# STM32U335 register map
File version: 1.0
CPU: CM33 r0p1, little endian, MPU, FPU, 4 interrupt priority bits
Registers are 32-bit, read-write, reset 0x0 unless marked. A register's access mark holds for its fields unless they carry their own. Offsets are from the block's base; [hi:lo] are bit positions; {n}, {i} and the like mark numbered series; <NAME> marks a mode.

## FLASH — FLASH register block
Base 0x40022000
Same registers: FLASH_S 0x50022000
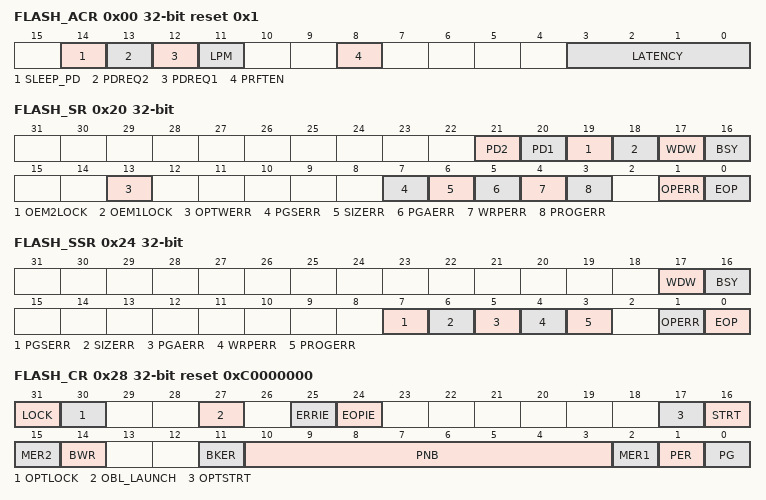
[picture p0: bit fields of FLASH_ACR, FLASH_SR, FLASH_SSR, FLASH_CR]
0x00 FLASH_ACR reset 0x1 — This register is nonsecure. It can be read and written by both secure and nonsecure access. This register can be protected against unprivileged access when PRIV = 1 in FLASH_PRIVCFGR register.
  [14] SLEEP_PD — Flash memory power-down mode during Sleep mode This bit determines whether the flash memory is in power-down mode or Idle mode when the device is in Sleep mode. The flash must not be put in power-down while a program or an erase operation is ongoing.
    0=Flash in Idle mode during Sleep mode; 1=Flash in power-down mode during Sleep mode
  [13] PDREQ2 — Bank 2 power-down mode request This bit is write-protected with FLASH_PDKEY2R. This bit requests bank 2 to enter power-down mode. When bank 2 enters power-down mode, this bit is cleared by hardware and FLASH_PDKEY2R is locked.
    0=No request for bank 2 to enter power-down mode; 1=Bank 2 requested to enter power-down mode
  [12] PDREQ1 — Bank 1 power-down mode request This bit is write-protected with FLASH_PDKEY1R. This bit requests bank 1 to enter power-down mode. When bank 1 enters power-down mode, this bit is cleared by hardware and FLASH_PDKEY1R is locked.
    0=No request for bank 1 to enter power-down mode; 1=Bank 1 requested to enter power-down mode
  [11] LPM — Low-power read mode This bit puts the flash memory in low-power read mode.
    0=FLASH not in low-power read mode; 1=FLASH in low-power read mode
  [8] PRFTEN — Prefetch enable This bit enables the prefetch buffer in the embedded flash memory.
    0=Prefetch disabled; 1=Prefetch enabled
  [3:0] LATENCY — Latency This bit field represents the ratio between the HCLK (AHB clock) period and the flash memory access time. ...
    0=0 wait state; 1=1 wait state; 2=2 wait states; 15=15 wait states
0x08 FLASH_KEYR wo — This register is nonsecure. It can be read and written by both secure and nonsecure access. This register can be protected against unprivileged access when PRIV =1 in FLASH_PRIVCFGR register.
  [31:0] KEY — Flash memory nonsecure key The following values must be written consecutively to unlock the FLASH_CR register, allowing flash memory nonsecure programming/erasing operations: KEY1: 0x4567 0123 KEY2: 0xCDEF 89AB
0x0C FLASH_SKEYR wo — This register is secure. It can be read and written only by secure access. A nonsecure read/write access is RAZ/WI. This register can be protected against unprivileged access when SPRIV = 1 in FLASH_PRIVCFGR register.
  [31:0] KEY — Flash memory secure key The following values must be written consecutively to unlock the FLASH_SCR register, allowing flash memory secure programming/erasing operations: KEY1: 0x4567 0123 KEY2: 0xCDEF 89AB
0x10 FLASH_OPTKEYR wo — This register is nonsecure. It can be read and written by both secure and nonsecure access. This register can be protected against unprivileged access when PRIV = 1 in FLASH_PRIVCFGR register.
  [31:0] KEY — Option-byte key The following values must be written consecutively to unlock the FLASH_OPTR register allowing option-byte programming/erasing operations: KEY1: 0x0819 2A3B KEY2: 0x4C5D 6E7F
0x18 FLASH_PDKEY1R wo — This register is nonsecure. It can be read and written by both secure and nonsecure access. This register can be protected against unprivileged access when PRIV = 1 in FLASH_PRIVCFGR register.
  [31:0] KEY1 — Bank 1 power-down key The following values must be written consecutively to unlock PDREQ1 bit in FLASH_ACR: KEY1_1: 0x0415 2637 KEY1_2: 0xFAFB FCFD
0x1C FLASH_PDKEY2R wo — This register is nonsecure. It can be read and written by both secure and nonsecure access. This register can be protected against unprivileged access when PRIV = 1 in FLASH_PRIVCFGR register.
  [31:0] KEY2 — Bank 2 power-down key The following values must be written consecutively to unlock PDREQ2 bit in FLASH_ACR: KEY2_1: 0x4051 6273 KEY2_2: 0xAFBF CFDF
0x20 FLASH_SR (reset mask 0xFFF0FFFF) — This register is nonsecure. It can be read and written by both secure and nonsecure access. This register can be protected against unprivileged access when PRIV = 1 in FLASH_PRIVCFGR register.
  [21] PD2 ro — Bank 2 in power-down mode This bit indicates that the flash memory bank 2 is in power-down state. It is reset when bank 2 is in normal mode or being awaken.
  [20] PD1 ro — Bank 1 in power-down mode This bit indicates that the flash memory bank 1 is in power-down state. It is reset when bank 1 is in normal mode or being awaken.
  [19] OEM2LOCK ro — OEM2 lock This bit indicates that the OEM2 RDP key read during the OBL is not virgin. When set, the OEM2 RDP lock mechanism is active.
  [18] OEM1LOCK ro — OEM1 lock This bit indicates that the OEM1 RDP key read during the OBL is not virgin. When set, the OEM1 RDP lock mechanism is active.
  [17] WDW ro — Nonsecure wait data to write This bit indicates that the flash memory write buffer has been written by a secure or nonsecure operation. It is set when the first data is stored in the buffer, and cleared when the write is performed in the flash memory.
  [16] BSY ro — Nonsecure busy This bit indicates that a flash memory secure or nonsecure operation is in progress. It is set at the beginning of a flash operation, and reset when the operation finishes or when an error occurs.
  [13] OPTWERR — Option write error This bit is set by hardware when the options bytes are written with an invalid configuration. It is cleared by writing 1. Refer to Section 7.3.8: Flash memory errors flags for full conditions of error flag setting.
  [7] PGSERR — Nonsecure programming sequence error This bit is set by hardware when programming sequence is not correct. It is cleared by writing 1. Refer to Section 7.3.8: Flash memory errors flags for full conditions of error flag setting.
  [6] SIZERR — Nonsecure size error This bit is set by hardware when the size of the access is a byte or half-word during a nonsecure program sequence. Only double-word programming is allowed by means of successive word accesses. This bit is cleared by writing 1.
  [5] PGAERR — Nonsecure programming alignment error This bit is set by hardware when the first word to be programmed is not aligned with a double-word address, or the second does not belong to the same double-word address. This bit is cleared by writing 1.
  [4] WRPERR — Nonsecure write protection error This bit is set by hardware when a nonsecure address to be erased/programmed belongs to a write-protected part (by WRP, HDP, or RDP level 1) of the flash memory. This bit is cleared by writing 1. Refer to Section 7.3.8: Flash memory errors flags for full conditions of error flag setting.
  [3] PROGERR — Nonsecure programming error This bit is set by hardware when a nonsecure double-word address to be programmed contains a value different from all 1 before programming, except if the data to write is all 0. This bit is cleared by writing 1.
  [1] OPERR — Nonsecure operation error This bit is set by hardware when a flash memory nonsecure operation (program/erase) completes unsuccessfully. This bit is set only if nonsecure error interrupts are enabled (ERRIE = 1 in FLASH_CR). This bit is cleared by writing 1.
  [0] EOP — Nonsecure end of operation This bit is set by hardware when one or more flash memory nonsecure operation (program/erase) has been completed successfully. This bit is set only if the nonsecure end of operation interrupts are enabled (EOPIE = 1 in FLASH_CR). This bit is cleared by writing 1.
0x24 FLASH_SSR — This register is secure. It can be read and written only by secure access. A nonsecure read/write access is RAZ/WI. This register can be protected against unprivileged access when SPRIV = 1 in FLASH_PRIVCFGR register.
  [17] WDW ro — Secure wait data to write This bit indicates that the flash memory write buffer has been written by a secure or nonsecure operation. It is set when the first data is stored in the buffer, and cleared when the write is performed in the flash memory.
  [16] BSY ro — Secure busy This bit indicates that a flash memory secure or nonsecure operation is in progress. This is set on the beginning of a flash operation, and reset when the operation finishes or when an error occurs.
  [7] PGSERR — Secure programming sequence error This bit is set by hardware when programming sequence is not correct. It is cleared by writing 1. Refer to Section 7.3.8: Flash memory errors flags for full conditions of error flag setting.
  [6] SIZERR — Secure size error This bit is set by hardware when the size of the access is a byte or half-word during a secure program sequence. Only double-word programming is allowed by means of successive word accesses.This bit is cleared by writing 1.
  [5] PGAERR — Secure programming alignment error This bit is set by hardware when the first word to be programmed is not aligned with a double-word address, or the second word does not belong to the same double-word address.This bit is cleared by writing 1.
  [4] WRPERR — Secure write protection error This bit is set by hardware when a secure address to be erased/programmed belongs to a write-protected part (by WRP, HDP, or RDP level 1) of the flash memory.This bit is cleared by writing 1. Refer to Section 7.3.8: Flash memory errors flags for full conditions of error flag setting.
  [3] PROGERR — Secure programming error This bit is set by hardware when a secure double-word address to be programmed contains a value different from all 1 before programming, except if the data to write is all 0. This bit is cleared by writing 1.
  [1] OPERR — Secure operation error This bit is set by hardware when a flash memory secure operation (program/erase) completes unsuccessfully. This bit is set only if secure error interrupts are enabled (ERRIE = 1 in FLASH_SCR). This bit is cleared by writing 1.
  [0] EOP — Secure end of operation This bit is set by hardware when one or more flash memory secure operation (program/erase) has been completed successfully. This bit is set only if the secure end of operation interrupts are enabled (EOPIE = 1 in FLASH_SCR). This bit is cleared by writing 1.
0x28 FLASH_CR reset 0xC0000000 — This register can only be written when the BSY or OBL_LAUNCH are reset. Otherwise, the write access is stalled until the BSY bits are reset. This register is nonsecure. It can be read and written by both secure and nonsecure access. This register can be protected against unprivileged access when PRIV = 1 in FLASH_PRIVCFGR register.
  [31] LOCK — Nonsecure lock This bit is set only. When set, the FLASH_CR register is locked. It is cleared by hardware after detecting the unlock sequence in FLASH_KEYR register. In case of an unsuccessful unlock operation, this bit remains set until the next system reset.
  [30] OPTLOCK — Option lock This bit is set only. When set, all bits concerning user options in FLASH_CR register are locked. This bit is cleared by hardware after detecting the unlock sequence. The LOCK bit in FLASH_CR must be cleared before doing the unlock sequence for OPTLOCK bit. In case of an unsuccessful unlock operation, this bit remains set until the next reset.
  [27] OBL_LAUNCH — Option-byte loading forced When set to 1, this bit forces the option-byte reloading. This bit is cleared only when the option-byte loading is complete. It cannot be written if OPTLOCK is set.
    0=Option-byte loading complete; 1=Option-byte loading requested
  [25] ERRIE — Nonsecure error interrupt enable This bit enables the interrupt generation when the OPERR bit in FLASH_SR is set to 1.
    0=Nonsecure OPERR error interrupt disabled; 1=Nonsecure OPERR error interrupt enabled
  [24] EOPIE — Nonsecure end of operation interrupt enable This bit enables the interrupt generation when the EOP bit in FLASH_SR is set to 1.
    0=Nonsecure EOP Interrupt disabled; 1=Nonsecure EOP Interrupt enabled
  [17] OPTSTRT — Option modification start This bit triggers an option operation when set. It can not be written if OPTLOCK bit is set. This bit is set only by software, and is cleared when the BSY bit is cleared in FLASH_SR.
  [16] STRT — Nonsecure start This bit triggers a nonsecure erase operation when set. If MER1, MER2, and PER bits are reset, and the STRT bit is set (this configuration is forbidden), the PGSERR bit in FLASH_SR is set . This bit is set only by software and is cleared when the BSY bit is cleared in FLASH_SR.
  [15] MER2 — Nonsecure bank 2 mass erase This bit triggers the bank 2 nonsecure mass erase (all bank 2 user pages) when set.
  [14] BWR — Nonsecure burst write programming mode When set, this bit selects the burst write programming mode.
  [11] BKER — Nonsecure bank selection for page erase
    0=Bank 1 selected for nonsecure page erase; 1=Bank 2 selected for nonsecure page erase
  [10:3] PNB — Nonsecure page number selection These bits select the page to erase. ... PNB[7] is reserved for STM32U375/385
    0=page 0; 1=page 1; 255=page 255
  [2] MER1 — Nonsecure bank 1 mass erase This bit triggers the bank 1 nonsecure mass erase (all bank 1 user pages) when set.
  [1] PER — Nonsecure page erase
    0=Nonsecure page erase disabled; 1=Nonsecure page erase enabled
  [0] PG — Nonsecure programming
    0=Nonsecure FLASH programming disabled; 1=Nonsecure FLASH programming enabled
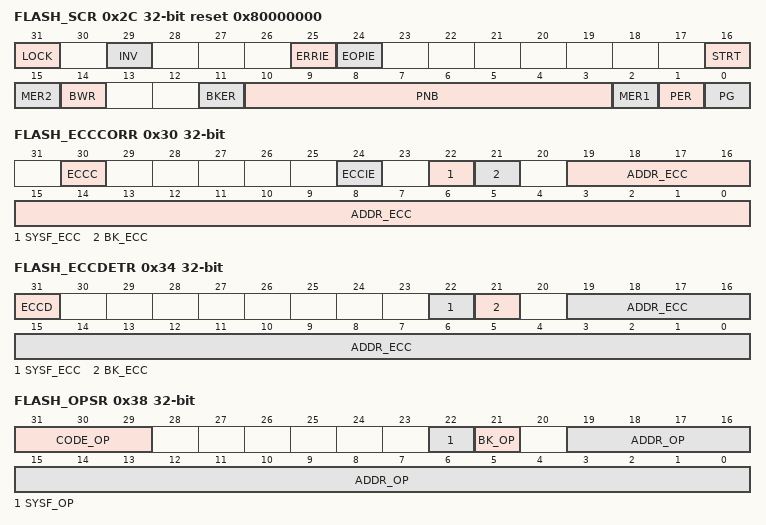
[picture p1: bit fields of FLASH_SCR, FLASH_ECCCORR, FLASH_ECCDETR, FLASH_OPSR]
0x2C FLASH_SCR reset 0x80000000 — This register can only be written when the BSY or OBL_LAUNCH are reset. Otherwise, the write access stalls until the BSY bits are reset. This register is secure. It can be read and written only by secure access. A nonsecure read/write access is RAZ/WI. This register can be protected against unprivileged access when SPRIV = 1 in FLASH_PRIVCFGR register.
  [31] LOCK — Secure lock This bit is set only. When set, the FLASH_SCR register is locked. This bit is cleared by hardware after detecting the unlock sequence in FLASH_SKEYR register. In case of an unsuccessful unlock operation, this bit remains set until the next system reset.
  [29] INV — Flash memory security state invert This bit inverts the flash memory security state.
  [25] ERRIE — Secure error interrupt enable This bit enables the interrupt generation when the OPERR bit in FLASH_SSR is set to 1.
    0=Secure OPERR error interrupt disabled; 1=Secure OPERR error interrupt enabled
  [24] EOPIE — Secure end of operation interrupt enable This bit enables the interrupt generation when the EOP bit in FLASH_SSR is set to 1.
    0=Secure EOP Interrupt disabled; 1=Secure EOP Interrupt enabled
  [16] STRT — Secure start This bit triggers a secure erase operation when set. If MER1, MER2, and PER bits are reset, and the STRT bit is set, the PGSERR in FLASH_SSR is set (this condition is forbidden). This bit is set only by software and is cleared when the BSY bit is cleared in FLASH_SSR.
  [15] MER2 — Secure bank 2 mass erase This bit triggers the bank 2 secure mass erase (all bank 2 user pages) when set.
  [14] BWR — Secure burst write programming mode When set, this bit selects the burst write programming mode.
  [11] BKER — Secure bank selection for page erase
    0=Bank 1 selected for secure page erase; 1=Bank 2 selected for secure page erase
  [10:3] PNB — Secure page number selection These bits select the page to erase: ... Note: PNB[7] is reserved for STM32U375/385
    0=page 0; 1=page 1
  [2] MER1 — Secure bank 1 mass erase This bit triggers the bank 1 secure mass erase (all bank 1 user pages) when set.
  [1] PER — Secure page erase
    0=Secure page erase disabled; 1=Secure page erase enabled
  [0] PG — Secure programming
    0=Secure FLASH programming disabled; 1=Secure FLASH programming enabled
0x30 FLASH_ECCCORR — This register is nonsecure. It can be read and written by both secure and nonsecure access. This register can be protected against unprivileged access when PRIV = 1 in FLASH_PRIVCFGR register.
  [30] ECCC — ECC correction This bit is set by hardware when one ECC error has been detected and corrected (only if ECCC was previously cleared). An interrupt is generated if ECCIE is set. This bit is cleared by writing 1.
  [24] ECCIE — ECC correction interrupt enable This bit enables the interrupt generation when the ECCC bit in FLASH_ECCR is set.
    0=ECCC interrupt disabled; 1=ECCC interrupt enabled
  [22] SYSF_ECC ro — System flash memory ECC fail This bit indicates that the ECC error correction or double ECC error detection is located in the system flash memory.
  [21] BK_ECC ro — ECC fail bank This bit indicates which bank is concerned by the ECC error correction.
    0=Bank 1; 1=Bank 2
  [19:0] ADDR_ECC ro — ECC fail address This bit field indicates which address is concerned by the ECC error correction. The address is given by bank from address 0x0 0000. Note: ADDR_ECC[19] is reserved for STM32U375/385.
0x34 FLASH_ECCDETR — This register is nonsecure. It can be read and written by both secure and nonsecure access. This register can be protected against unprivileged access when PRIV = 1 in FLASH_PRIVCFGR register.
  [31] ECCD — ECC detection This bit is set by hardware when two ECC errors have been detected (only if ECCD was previously cleared). When this bit is set, a NMI is generated. This bit is cleared by writing 1.
  [22] SYSF_ECC ro — System flash memory ECC fail This bit indicates that the double ECC error detection is located in the system flash memory.
  [21] BK_ECC ro — ECC fail bank This bit indicates which bank is concerned by the double ECC error detection.
    0=Bank 1; 1=Bank 2
  [19:0] ADDR_ECC ro — ECC fail address This bit field indicates which address is concerned by the double ECC error detection. The address is given by bank from address 0x0 0000. Note: ADDR_ECC[19] is reserved for STM32U375/385.
0x38 FLASH_OPSR ro (reset mask 0xF000000) — System reset value: 0xX0XX XXXX Power-on reset value: 0xX0XX XXXX This register is nonsecure. It can be read and written by both secure and nonsecure access. This register can be protected against unprivileged access when PRIV = 1 in FLASH_PRIVCFGR register.
  [31:29] CODE_OP — Flash memory operation code This bit field indicates which flash memory operation has been interrupted by a system reset:
    0=No flash operation interrupted by previous reset; 1=Single write operation interrupted; 2=Burst write operation interrupted; 3=Page erase operation interrupted; 4=Bank erase operation interrupted; 5=Mass erase operation interrupted; 6=Option change operation interrupted
  [22] SYSF_OP — Operation in system flash memory interrupted This bit indicates that the reset occurred during an operation in the system flash memory.
  [21] BK_OP — Interrupted operation bank This bit indicates which flash memory bank was accessed when reset occurred
    0=Bank 1; 1=Bank 2
  [19:0] ADDR_OP — Interrupted operation address This bit field indicates which address in the flash memory was accessed when reset occurred. The address is given by bank from address 0x0 0000. Note: ADDR_OP[19] is reserved for STM32U375/385.
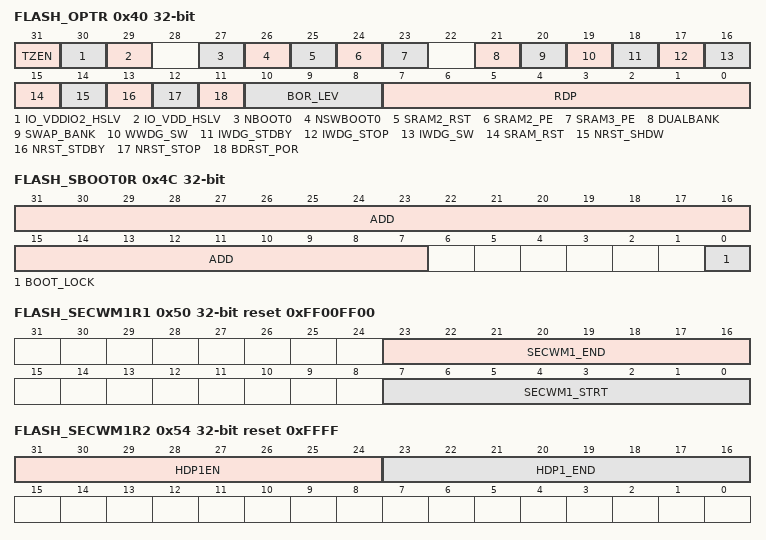
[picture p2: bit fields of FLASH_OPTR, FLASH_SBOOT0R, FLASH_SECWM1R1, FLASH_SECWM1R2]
0x40 FLASH_OPTR reset not defined — This register is nonsecure. It can be read and written by both secure and nonsecure access. This register can be protected against unprivileged access when PRIV = 1 in FLASH_PRIVCFGR register. ST production value: 0x1FEF F0AA (register bits 0 to 31 are loaded with values from the flash memory at OBL)
  [31] TZEN — Global TrustZone security enable
    0=Global TrustZone security disabled; 1=Global TrustZone security enabled
  [30] IO_VDDIO2_HSLV — High-speed I/O at low V<sub>DDIO2</sub> voltage configuration bit This bit can be set only with V<sub>DDIO2</sub> below 2.5 V.
    0=High-speed I/O at low V<sub>DDIO2 </sub>voltage feature disabled (V<sub>DDIO2</sub> can exceed 2.5 V); 1=High-speed I/O at low V<sub>DDIO2 </sub>voltage feature enabled (V<sub>DDIO2</sub> remains below 2.5 V)
  [29] IO_VDD_HSLV — High-speed I/O at low V<sub>DD </sub>voltage configuration bit This bit can be set only with V<sub>DD</sub> below 2.5V
    0=High-speed I/O at low V<sub>DD </sub>voltage feature disabled (V<sub>DD</sub> can exceed 2.5 V); 1=High-speed I/O at low V<sub>DD </sub>voltage feature enabled (V<sub>DD</sub> remains below 2.5 V)
  [27] NBOOT0 — NBOOT0 option bit
    0=NBOOT0 = 0; 1=NBOOT0 = 1
  [26] NSWBOOT0 — Software BOOT0
    0=BOOT0 taken from the option bit NBOOT0; 1=BOOT0 taken from PH3/BOOT0 pin
  [25] SRAM2_RST — SRAM2 erase when system reset
    0=SRAM2 erased when a system reset occurs; 1=SRAM2 not erased when a system reset occurs
  [24] SRAM2_PE — SRAM2 parity check enable
    0=SRAM2 parity check enabled; 1=SRAM2 parity check disabled
  [23] SRAM3_PE — SRAM3 parity check enable
    0=SRAM3 parity check enabled; 1=SRAM3 parity check disabled
  [21] DUALBANK — Dual-bank on 512-Kbyte flash memory devices
    0=Single-bank FLASH with contiguous address in bank 1; 1=Dual-bank FLASH with contiguous addresses
  [20] SWAP_BANK — Swap banks
    0=Bank 1 and bank 2 addresses not swapped; 1=Bank 1 and bank 2 addresses swapped
  [19] WWDG_SW — Window watchdog selection
    0=Hardware WWDG selected; 1=Software WWDG selected
  [18] IWDG_STDBY — Independent watchdog counter freeze in Standby mode
    0=IWDG counter frozen in Standby mode; 1=IWDG counter running in Standby mode
  [17] IWDG_STOP — Independent watchdog counter freeze in Stop mode
    0=IWDG counter frozen in Stop mode; 1=IIWDG counter running in Stop mode
  [16] IWDG_SW — Independent watchdog selection
    0=Hardware IWDG selected; 1=Software IWDG selected
  [15] SRAM_RST — All SRAMs (except SRAM2 and SRAM4) erase upon system reset Note: SRAM4 is not available in STM32U375/385.
    0=All SRAMs (except SRAM2 and SRAM4) erased when a system reset occurs; 1=All SRAMs (except SRAM2 and SRAM4) not erased when a system reset occurs
  [14] NRST_SHDW — Reset generation in Shutdown mode
    0=Reset generated when entering the Shutdown mode; 1=No reset generated when entering the Shutdown mode
  [13] NRST_STDBY — Reset generation in Standby mode
    0=Reset generated when entering the Standby mode; 1=No reset generate when entering the Standby mode
  [12] NRST_STOP — Reset generation in Stop mode
    0=Reset generated when entering the Stop mode; 1=No reset generated when entering the Stop mode
  [11] BDRST_POR — Backup domain reset with power-on reset
    0=The backup domain is not reset after a V<sub>DD</sub> domain brownout reset (BOR). This configuration must be used when V<sub>BAT</sub> supply source is different from V<sub>DD</sub>.; 1=The backup domain is reset after a V<sub>DD</sub> domain brownout reset (BOR). This configuration must be used when the V<sub>BAT</sub> and V<sub>DD</sub> are connected together. It is forbidden when V<sub>BAT</sub> supply source is different from V<sub>DD</sub>.
  [10:8] BOR_LEV — BOR reset level This bit field contains the V<sub>DD</sub> supply level threshold that activates/releases the reset.
    0=BOR level 0 (reset level threshold around 1.7 V); 1=BOR level 1 (reset level threshold around 2.0 V); 2=BOR level 2 (reset level threshold around 2.2 V); 3=BOR level 3 (reset level threshold around 2.5 V); 4=BOR level 4 (reset level threshold around 2.8 V)
  [7:0] RDP — Readout protection level Others: Level 1 (memories readout protection active) Note: Refer to Section 7.6.2: Readout protection (RDP) for more details.
    170=Level 0 (readout protection not active); 85=Level 0.5 (readout protection not active, only nonsecure debug access is possible). Only available when TrustZone is active (TZEN = 1); 204=Level 2 (chip readout protection active)
0x44 FLASH_BOOT0R reset 0xF (reset mask 0xF) — This register can not be written if OPTLOCK bit is set. This register is nonsecure. It can be read and written by both secure and nonsecure access. This register can be protected against unprivileged access when PRIV = 1 in FLASH_PRIVCFGR register. ST production value: 0x0800 007F (option bytes are loaded with values from the flash memory at reset release)
  [31:7] ADD — Nonsecure boot base address 0 The nonsecure boot memory address can be programmed to any address in the valid address range with a granularity of 128 bytes. These bits correspond to address [31:7]. ADD option bytes are selected following the BOOT0 pin or NSWBOOT0 state. Examples: ADD[24:0] = 0x0100000: Boot from nonsecure flash memory (0x0800 0000) ADD[24:0] = 0x017F1E0: Boot from system memory bootloader (0x0BF8 F000) ADD[24:0] = 0x0400000: Boot from nonsecure SRAM1 on S-Bus (0x2000 0000)
0x48 FLASH_BOOT1R reset 0xF (reset mask 0xF) — This register can not be written if OPTLOCK bit is set. This register is nonsecure. It can be read and written by both secure and nonsecure access. This register can be protected against unprivileged access when PRIV = 1 in FLASH_PRIVCFGR register. ST production value: 0x0BF8 F07F (option bytes are loaded with values from the flash memory at reset release)
  [31:7] ADD — nonsecure boot address 1 The nonsecure boot memory address can be programmed to any address in the valid address range with a granularity of 128 bytes. These bits correspond to address [31:7]. ADD option bytes are selected following the BOOT0 pin or nSWBOOT0 state. Examples: ADD[24:0] = 0x0100000: Boot from nonsecure flash memory (0x0800 0000) ADD[24:0] = 0x017F1E0: Boot from system memory bootloader (0x0BF8 F000) ADD[24:0] = 0x0400000: Boot from nonsecure SRAM1 on S-Bus (0x2000 0000)
0x4C FLASH_SBOOT0R reset not defined — This register can not be written if OPTLOCK bit is set. This register is secure. It can be read and written only by secure access. A nonsecure read/write access is RAZ/WI. This register can be protected against unprivileged access when SPRIV = 1 in FLASH_PRIVCFGR register. ST production value: 0x0C00 007C (option bytes are loaded with values from the flash memory at reset release)
  [31:7] ADD — Secure boot base address 0 The secure boot memory address can be programmed to any address in the valid address range with a granularity of 128 bytes. This bits correspond to address [31:7] ADD option bytes are selected following the BOOT0 pin or NSWBOOT0 state. Examples: ADD[24:0] = 0x018 0000: Boot from secure flash memory (0x0C00 0000) ADD[24:0] = 0x01F F000: Boot from RSS (0x0FF8 0000) ADD[24:0] = 0x060 0000: Boot from secure SRAM1 on S-Bus (0x3000 0000)
  [0] BOOT_LOCK — Boot lock When set, the boot is always forced to base address value programmed in ADD[24:0] option bytes, whatever the boot selection option. When set, this bit can only be cleared when RDP is at level 0.
0x50 FLASH_SECWM1R1 reset 0xFF00FF00 (reset mask 0xFF00FF00) — This register can not be written if OPTLOCK bit is set. This register is secure. It can be read and written only by secure access. A nonsecure read/write access is RAZ/WI. This register can be protected against unprivileged access when SPRIV = 1 in FLASH_PRIVCFGR register. ST production value: - 0xFFFF FF80 (for STM32U375/385) - 0xFFFF FF00 (for STM32U3B5/3C5) (register bits are loaded with values from the flash memory at OBL. Reserved bits are read as 1.)
  [23:16] SECWM1_END — End page of first secure area This bit field contains the last page of the secure area in bank 1. Note: SECWM1_END[7] is reserved for STM32U375/385.
  [7:0] SECWM1_STRT — Start page of first secure area This bit field contains the first page of the secure area in bank 1. Note: SECWM1_STRT[7] is reserved for STM32U375/385.
0x54 FLASH_SECWM1R2 reset 0xFFFF (reset mask 0xFFFF) — This register can not be written if OPTLOCK bit is set. This register is secure. It can be read and written only by secure access. A nonsecure read/write access is RAZ/WI. This register can be protected against unprivileged access when SPRIV = 1 in FLASH_PRIVCFGR register. ST production value: - 0xB480 FFFF (for STM32U375/385) - 0xB400 FFFF (for STM32U3B5/3C5) (register bits are loaded with values from the flash memory at OBL)
  [31:24] HDP1EN — Hide protection first area enable others: HDP first area enabled
    180=No HDP area 1
  [23:16] HDP1_END — End page of first hide protection area This bit field contains the last page of the HDP area in bank 1. Note: HDP1_END[7] is reserved for STM32U375/385
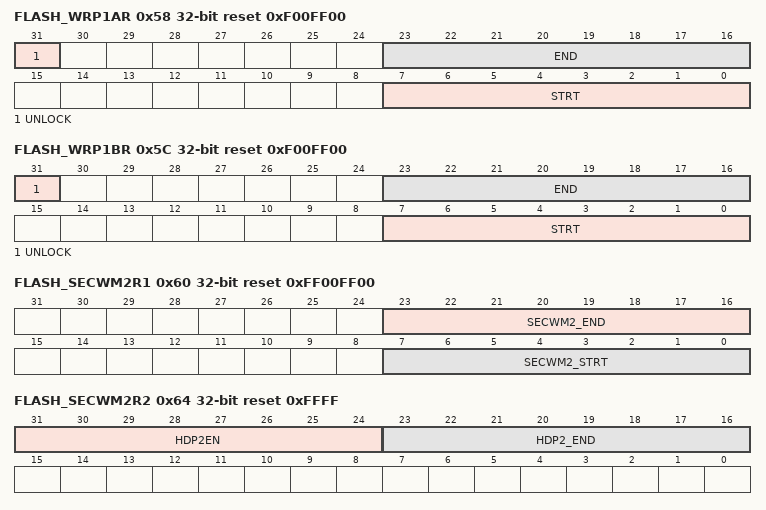
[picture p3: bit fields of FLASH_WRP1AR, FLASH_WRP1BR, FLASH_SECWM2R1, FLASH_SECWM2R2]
0x58 FLASH_WRP1AR reset 0xF00FF00 (reset mask 0xF00FF00) — This register can not be written if OPTLOCK bit is set. This register is nonsecure. It can be read and written by both secure and nonsecure access. This register can be protected against unprivileged access when PRIV = 1 in FLASH_PRIVCFGR register. ST production value: - 0xFF80 FFFF (for STM32U375/385) - 0xFF00 FFFF (forSTM32U3B5/3C5) (register bits are loaded with values from the flash memory at OBL. Reserved bits are read as 1)
  [31] UNLOCK — Bank 1 WPR first area A unlock
    0=WRP1A start and end pages locked; 1=WRP1A start and end pages unlocked
  [23:16] END — Bank 1 WPR first area A end page This bit field contains the last page of the first WPR area in bank 1. Note: END[7] is reserved for STM32U375/385.
  [7:0] STRT — Bank 1 WPR first area A start page This bit field contains the first page of the first WPR area for bank 1. Note: STRT[7] is reserved for STM32U375/385.
0x5C FLASH_WRP1BR reset 0xF00FF00 (reset mask 0xF00FF00) — This register can not be written if OPTLOCK bit is set. This register is nonsecure. It can be read and written by both secure and nonsecure access. This register can be protected against unprivileged access when PRIV = 1 in FLASH_PRIVCFGR register. ST production value: - 0xFF80 FFFF (for STM32U375/385) - 0xFF00 FFFF (forSTM32U3B5/3C5) (register bits are loaded with values from the flash memory at OBL)
  [31] UNLOCK — Bank 1 WPR second area B unlock
    0=WRP1B start and end pages locked; 1=WRP1B start and end pages unlocked
  [23:16] END — Bank 1 WRP second area B end page This bit field contains the last page of the second WRP area in bank 1. Note: END[7] is reserved for STM32U375/385.
  [7:0] STRT — Bank 1 WRP second area B start page This bit field contains the first page of the second WRP area for bank 1. Note: STRT[7] is reserved for STM32U375/385.
0x60 FLASH_SECWM2R1 reset 0xFF00FF00 (reset mask 0xFF00FF00) — This register can not be written if OPTLOCK bit is set. This register is secure. It can be read and written only by secure access. A nonsecure read/write access is RAZ/WI. This register can be protected against unprivileged access when SPRIV = 1 in FLASH_PRIVCFGR register. ST production value: - 0xFFFF FF80 (for STM32U375/385) - 0xFFFF FF00 (forSTM32U3B5/3C5) (register bits are loaded with values from the flash memory at OBL)
  [23:16] SECWM2_END — End page of second secure area This bit field contains the last page of the secure area in bank 2. Note: SECWM2_END[7] is reserved for STM32U375/385.
  [7:0] SECWM2_STRT — Start page of second secure area This bit field contains the first page of the secure area in bank 2. Note: SECWM2_STRT[7] is reserved for STM32U375/385.
0x64 FLASH_SECWM2R2 reset 0xFFFF (reset mask 0xFFFF) — This register can not be written if OPTLOCK bit is set. This register is secure. It can be read and written only by secure access. A nonsecure read/write access is RAZ/WI. This register can be protected against unprivileged access when SPRIV = 1 in FLASH_PRIVCFGR register. ST production value: - 0xB480 FFFF (for STM32U375/385) - 0xB400 FFFF (forSTM32U3B5/3C5) (register bits are loaded with values from the flash memory at OBL)
  [31:24] HDP2EN — Hide protection second area enable others: HDP second area is enabled.
    180=No HDP area 2
  [23:16] HDP2_END — End page of hide protection second area This bit field contains the last page of the HDP area in bank 2. Note: HDP2_END[7] is reserved for STM32U375/385.
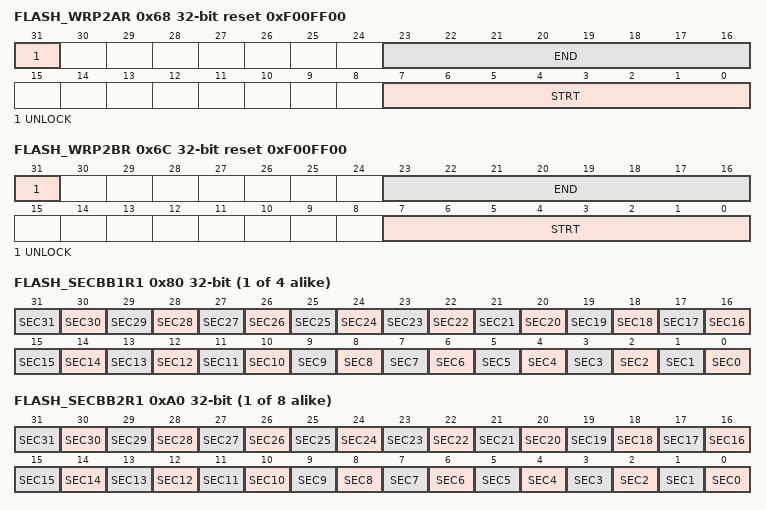
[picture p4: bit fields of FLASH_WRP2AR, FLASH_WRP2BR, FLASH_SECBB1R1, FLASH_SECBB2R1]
0x68 FLASH_WRP2AR reset 0xF00FF00 (reset mask 0xF00FF00) — This register can not be written if OPTLOCK bit is set. This register is nonsecure. It can be read and written by both secure and nonsecure access. This register can be protected against unprivileged access when PRIV = 1 in FLASH_PRIVCFGR register. ST production value: - 0xFF80 FFFF (for STM32U375/385) - 0xFF00 FFFF (forSTM32U3B5/3C5) (register bits are loaded with values from the flash memory at OBL)
  [31] UNLOCK — Bank 2 WPR first area A unlock
    0=WRP2A start and end pages locked; 1=WRP2A start and end pages unlocked
  [23:16] END — Bank 2 WPR first area A end page This bit field contains the last page of the first WRP area in bank 2. Note: END[7] is reserved for STM32U375/385.
  [7:0] STRT — Bank 2 WPR first area A start page This bit field contains the first page of the first WRP area for bank 2. Note: STRT[7] is reserved for STM32U375/385.
0x6C FLASH_WRP2BR reset 0xF00FF00 (reset mask 0xF00FF00) — This register can not be written if OPTLOCK bit is set. This register is nonsecure. It can be read and written by both secure and nonsecure access. This register can be protected against unprivileged access when PRIV = 1 in FLASH_PRIVCFGR register. ST production value: - 0xFF80 FFFF (for STM32U375/385) - 0xFF00 FFFF (for STM32U3B5/3C5) (register bits are loaded with values from the flash memory at OBL)
  [31] UNLOCK — Bank 2 WPR second area B unlock
    0=WRP2B start and end pages locked; 1=WRP2B start and end pages unlocked
  [23:16] END — Bank 2 WPR second area B end page This bit field contains the last page of the second WRP area in bank 2. Note: END[7] is reserved for STM32U375/385.
  [7:0] STRT — Bank 2 WPR second area B start page This bit field contains the first page of the second WRP area for bank 2. Note: STRT[7] is reserved for STM32U375/385.
{0x7C+4i} FLASH_SECBB1R{i} (i=1..4) — This register is secure. It can be written only by secure access. This register can be protected against unprivileged access (refer to Table 66: FLASH_SECBByRx registers access when TrustZone is active (TZEN = 1)).
  [all] fields
    0=Page (32 * (x - 1) + i) in bank 1 not block-based secure; 1=Page (32 * (x - 1) + i) in bank 1 block-based secure
  [n] SEC{n} (n=0..31) — Page secure/nonsecure attribution Each bit is used to set one page security attribution in bank 1.
{0x9C+4i} FLASH_SECBB2R{i} (i=1..8) — This register is secure. It can be written only by a secure access. This register can be protected against unprivileged access (refer to Table 66: FLASH_SECBByRx registers access when TrustZone is active (TZEN = 1)).
  [all] fields
    0=Page (32 * (x - 1) + i) in bank 2 not block-based secure; 1=Page (32 * (x - 1) + i) in bank 2 block-based secure
  [n] SEC{n} (n=0..31) — Page secure/nonsecure attribution Each bit is used to set one page security attribution in bank 2.
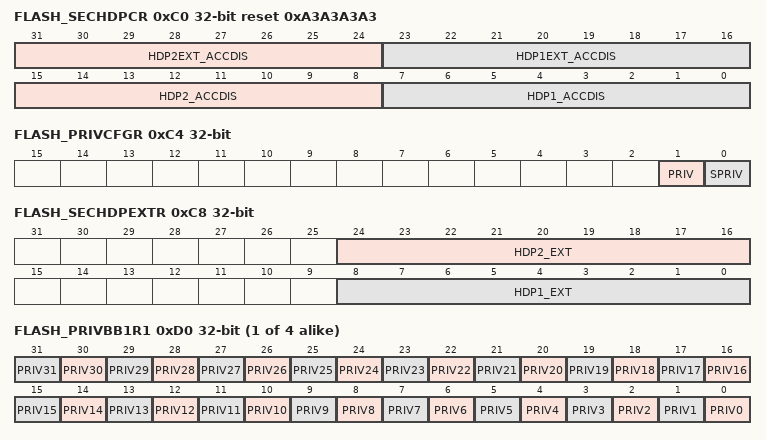
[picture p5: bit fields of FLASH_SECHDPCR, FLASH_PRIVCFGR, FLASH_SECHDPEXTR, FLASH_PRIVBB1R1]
0xC0 FLASH_SECHDPCR reset 0xA3A3A3A3 — This register is secure. It can be read and written only by secure access. A nonsecure read/write access is RAZ/WI. This register can be protected against unprivileged access when SPRIV = 1 in FLASH_PRIVCFGR register.
  [31:24] HDP2EXT_ACCDIS — HDP2 extension area access disable Register access depends on its current value. Refer to HDP extension area access for the full conditions. Others: Access to HDP2 extension area and HDP2 area denied. Update of HDP2_EXT size is not possible anymore .(SECWM2Ry option bytes modification blocked - refer to Rules for modifying specific option bytes)
    163=Access to HDP2 extension area granted; 92=Access to HDP2 extension area and HDP2 area denied, but HDP2_EXT (in FLASH_HDPEXTR) increment allowed at any time. (SECWM2Ry option bytes modification blocked - refer to Rules for modifying specific option bytes).
  [23:16] HDP1EXT_ACCDIS — HDP1 extension area access disable Register access depends on its current value. Refer to HDP extension area access for the full conditions. Others: Access to HDP1 extension area and HDP1 area denied. update of HDP1_EXT size is not possible anymore .(SECWM1Ry option bytes modification blocked - refer to Rules for modifying specific option bytes)
    163=Access to HDP1 extension area granted; 92=Access to HDP1 extension area and HDP1 area denied, but HDP1_EXT (in FLASH_HDPEXTR) increment allowed at any time. (SECWM1Ry option bytes modification blocked - refer to Rules for modifying specific option bytes)
  [15:8] HDP2_ACCDIS — HDP2 area access disable When set to a value different than 0xA3, this bit field cannot be modified except by a system reset. Others: Access to HDP2 area denied (SECWM2Ry option-byte modification blocked - refer to Rules for modifying specific option bytes). When HDP2_ACCDIS value is different than 0xA3, any write access to HDP2_ACCDIS is ignored.
    163=Access to HDP2 area granted
  [7:0] HDP1_ACCDIS — HDP1 area access disable When set to a value different than 0xA3, this bit field cannot be modified except by a system reset. Others: Access to HDP1 area denied (SECWM1Ry option bytes modification blocked - refer to Rules for modifying specific option bytes). When HDP1_ACCDIS value is different than 0xA3, any write access to HDP1_ACCDIS is ignored.
    163=Access to HDP1 area granted
0xC4 FLASH_PRIVCFGR — This register can be read by both privileged and unprivileged access. PRIV is a nonsecure bit. SPRIV is a secure bit.
  [1] PRIV — Privileged protection for nonsecure registers This bit can be read by both privileged or unprivileged, secure and nonsecure access. This bit can be written by a secure or nonsecure privileged access. A secure or nonsecure unprivileged write access on PRIV bit is ignored
    0=Nonsecure FLASH registers can be read and written by privileged or unprivileged access; 1=Nonsecure FLASH registers can be read and written by privileged access only
  [0] SPRIV — Privileged protection for secure registers This bit can be accessed only when TrustZone is enabled (TZEN = 1). This bit can be read by both privileged or unprivileged, secure and nonsecure access. This bit can be written only by a secure privileged access. A nonsecure write access on SPRIV bit is ignored. A secure unprivileged write access on SPRIV bit is ignored.
    0=Secure FLASH registers can be read and written by privileged or unprivileged access; 1=Secure FLASH registers can be read and written by privileged access only
0xC8 FLASH_SECHDPEXTR — This register is secure. It can be read and written only by secure access. This register can be protected against unprivileged access when SPRIV = 1 in FLASH_PRIVCFGR register.
  [24:16] HDP2_EXT — HDP area extension in 4-Kbyte pages in bank 2 The extension starts at page offset HDP2_END+1 if HDP2 area is enable (HDP2EN = 0xB4). Otherwise, it starts at page offset SECWM2_STRT. Register access depends on HDP2EXT_ACCDIS value (Refer to HDP extension area access for the full conditions). Note: HDP2_EXT[8] is reserved for STM32U375/385.
  [8:0] HDP1_EXT — HDP area extension in 4-Kbyte pages in bank 1 The extension starts at page offset HDP1_END+1 if HDP1 area is enable (HDP1EN = 0xB4). Otherwise, it starts at page offset SECWM1_STRT. Register access depends on HDP1EXT_ACCDIS value (refer to HDP extension area access for the full conditions. Note: HDP1_EXT[8] is reserved for STM32U375/385.
{0xCC+4i} FLASH_PRIVBB1R{i} (i=1..4) — This register is privileged. It can be read written only by a privileged access. This register can be protected against nonsecure access (refer to Table 67: FLASH_PRIVBByRx registers access when TrustZone is active (TZEN = 1)).
  [all] fields
    0=Page (32 * (x - 1) + i) in bank 1 accessible by unprivileged access; 1=Page (32 * (x - 1) + i) in bank 1 only accessible by privileged access
  [n] PRIV{n} (n=0..31) — Page privileged/unprivileged attribution Each bit is used to set one page privilege attribution in bank 1.
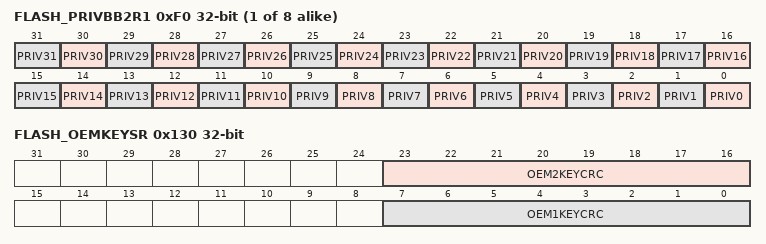
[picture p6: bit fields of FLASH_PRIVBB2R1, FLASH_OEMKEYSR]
{0xEC+4i} FLASH_PRIVBB2R{i} (i=1..8) — This register is privilege. It can be read written only by a privileged access. This register can be protected against nonsecure access (refer to Table 67: FLASH_PRIVBByRx registers access when TrustZone is active (TZEN = 1)).
  [all] fields
    0=Page (32 * (x - 1) + i) in bank 2 accessible by unprivileged access; 1=Page (32 * (x - 1) + i) in bank 2 only accessible by privileged access
  [n] PRIV{n} (n=0..31) — Page privileged/unprivileged attribution Each bit is used to set one page security attribution in bank 2.
{0x10C+4i} FLASH_OEM1KEYR{i} wo (i=1..3) — This register is nonsecure. It can be written by both secure and nonsecure access. This register is read as zero. This register can be protected against unprivileged access when PRIV = 1 in FLASH_PRIVCFGR register.
  [31:0] OEM1KEY — OEM1[{32i-1}:{32i-32}] bytes key
0x11C FLASH_OEM1KEYR4 wo — This register is nonsecure. It can be written by both secure and nonsecure access. This register can be protected against unprivileged access when PRIV = 1 in FLASH_PRIVCFGR register.
  [31:0] OEM1KEY — OEM1[127:96] bytes key
{0x11C+4i} FLASH_OEM2KEYR{i} wo (i=1..3) — This register is nonsecure. It can be written by both secure and nonsecure access. This register is read as zero. This register can be protected against unprivileged access when PRIV = 1 in FLASH_PRIVCFGR register.
  [31:0] OEM2KEY — OEM2[{32i-1}:{32i-32}] bytes key
0x12C FLASH_OEM2KEYR4 wo — This register is nonsecure. It can be written by both secure and nonsecure access. This register can be protected against unprivileged access when PRIV = 1 in FLASH_PRIVCFGR register.
  [31:0] OEM2KEY — OEM2[127:96] bytes key
0x130 FLASH_OEMKEYSR ro (reset mask 0xFF00FF00) — This register is nonsecure. It can be read by both secure and nonsecure access. This register can be protected against unprivileged access when PRIV = 1 in FLASH_PRIVCFGR register.
  [23:16] OEM2KEYCRC — 8-bit OEM2KEY CRC CRC is automatically computed by hardware while loading the OEM2KEYkey. The CRC computation is an 8-bit checksum using the standard CRC-8-CCITT algorithm X8 + X2 + X + 1 (according the convention). Source code is available in OEM Key CRC source. Note: CRC information is updated each time FLASH OEM2KEY registers are written
  [7:0] OEM1KEYCRC — 8-bit OEMKEY1 CRC CRC is automatically computed by hardware while loading the OEM1KEY key. The CRC computation is an 8-bit checksum using the standard CRC-8-CCITT algorithm X8 + X2 + X + 1 (according the convention). Source code is available in OEM Key CRC source. Note: CRC information is updated each time FLASH OEM1KEY registers are written

## Notices in the file
Copyright (c) 2026 STMicroelectronics.
SPDx-License-Identifier: Apache-2.0
Licensed under the Apache License, Version 2.0 (the "License");
you may not use this file except in compliance with the License.
You may obtain a copy of the License at
http://www.apache.org/licenses/LICENSE-2.0
Unless required by applicable law or agreed to in writing, software
distributed under the License is distributed on an "AS IS" BASIS,
WITHOUT WARRANTIES OR CONDITIONS OF ANY KIND, either express or implied.
See the License for the specific language governing permissions and
limitations under the License.
